# wdt_revb register map
Registers are read-write, no defined reset value unless marked. A register's access mark holds for its fields unless they carry their own. Offsets are from the block's base; lines under a group give offsets from that group; [hi:lo] are bit positions; {n}, {i} and the like mark numbered series; 'fields as' and 'values as' point back to an identical list; <NAME> marks a mode.

## Memory map
0x40003000 WDT size 0x400 — Windowed Watchdog Timer

## Interrupts
1 WWDT (WDT)

## WDT — Windowed Watchdog Timer
Base 0x40003000
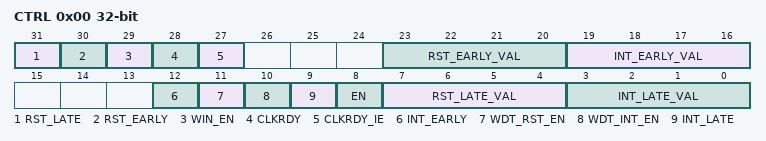
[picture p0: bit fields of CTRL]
0x00 CTRL — Watchdog Timer Control Register.
  [31] RST_LATE — Windowed Watchdog Timer Reset Flag Too Late.
    0=noEvent (The event has not occurred.); 1=occurred (The event has occurred.)
  [30] RST_EARLY — Windowed Watchdog Timer Reset Flag Too Soon.
    values as RST_LATE
  [29] WIN_EN — Enables the Windowed Watchdog Function.
    0=dis (Windowed Mode Disabled (i.e. Compatibility Mode).); 1=en (Windowed Mode Enabled.)
  [28] CLKRDY — Clock Status.
  [27] CLKRDY_IE — Switch Ready Interrupt Enable. Fires an interrupt when it is safe to swithc the clock.
  [23:20] RST_EARLY_VAL — Windowed Watchdog Reset Lower Limit. Sets the number of WDTCLK cycles that establishes the lower boundary of the watchdog window. A system reset occurs (if enabled) if the CPU writes the windowed watchdog reset sequence to the WWDT_RST register before the watchdog timer has counted this time period since the last timer reset.
    0=wdt2pow31 (2**31 clock cycles.); 1=wdt2pow30 (2**30 clock cycles.); 2=wdt2pow29 (2**29 clock cycles.); 3=wdt2pow28 (2**28 clock cycles.); 4=wdt2pow27 (2^27 clock cycles.); 5=wdt2pow26 (2**26 clock cycles.); 6=wdt2pow25 (2**25 clock cycles.); 7=wdt2pow24 (2**24 clock cycles.); 8=wdt2pow23 (2**23 clock cycles.); 9=wdt2pow22 (2**22 clock cycles.); 10=wdt2pow21 (2**21 clock cycles.); 11=wdt2pow20 (2**20 clock cycles.); 12=wdt2pow19 (2**19 clock cycles.); 13=wdt2pow18 (2**18 clock cycles.); 14=wdt2pow17 (2**17 clock cycles.); 15=wdt2pow16 (2**16 clock cycles.)
  [19:16] INT_EARLY_VAL — Windowed Watchdog Interrupt Lower Limit. Sets the number of WDTCLK cycles that establishes the lower boundary of the watchdog window. A windowed watchdog timer interrupt is generated (if enabled) if the CPU writes the windowed watchdog reset sequence to the WWDT_RST register before the watchdog timer has counted this time period since the last timer reset.
    values as RST_EARLY_VAL
  [12] INT_EARLY — Windowed Watchdog Timer Interrupt Flag Too Soon.
    0=inactive (No interrupt is pending.); 1=pending (An interrupt is pending.)
  [11] WDT_RST_EN — Windowed Watchdog Timer Reset Enable.
    0=dis (Disable.); 1=en (Enable.)
  [10] WDT_INT_EN — Windowed Watchdog Timer Interrupt Enable.
    0=dis (Disable.); 1=en (Enable.)
  [9] INT_LATE — Windowed Watchdog Timer Interrupt Flag Too Late.
    values as INT_EARLY
  [8] EN — Windowed Watchdog Timer Enable.
    0=dis (Disable.); 1=en (Enable.)
  [7:4] RST_LATE_VAL — Windowed Watchdog Reset Upper Limit. Sets the number of WDTCLK cycles until a system reset occurs (if enabled) if the CPU does not write the watchdog reset sequence to the WDT_RST register before the watchdog timer has counted this time period since the last timer reset.
    values as RST_EARLY_VAL
  [3:0] INT_LATE_VAL — Windowed Watchdog Interrupt Upper Limit. Sets the number of WDTCLK cycles until a windowed watchdog timer interrupt is generated (if enabled) if the CPU does not write the windowed watchdog reset sequence to the WWDT_RST register before the watchdog timer has counted this time period since the last timer reset.
    values as RST_EARLY_VAL
0x04 RST wo — Windowed Watchdog Timer Reset Register.
  [7:0] RESET — Writing the watchdog counter 'reset sequence' to this register resets the watchdog counter. If the watchdog count exceeds INT_PERIOD_UPPER_LIMIT then a watchdog interrupt will occur, if enabled. If the watchdog count exceeds RST_PERIOD_UPPER_LIMIT then a watchdog reset will occur, if enabled.
    165=seq0 (The first value to be written to reset the WDT.); 90=seq1 (The second value to be written to reset the WDT.)
0x08 CLKSEL — Windowed Watchdog Timer Clock Select Register.
  [2:0] SOURCE — WWDT Clock Selection Register.
0x0C CNT ro — Windowed Watchdog Timer Count Register.
  [31:0] COUNT — Current Value of the Windowed Watchdog Timer Counter.
